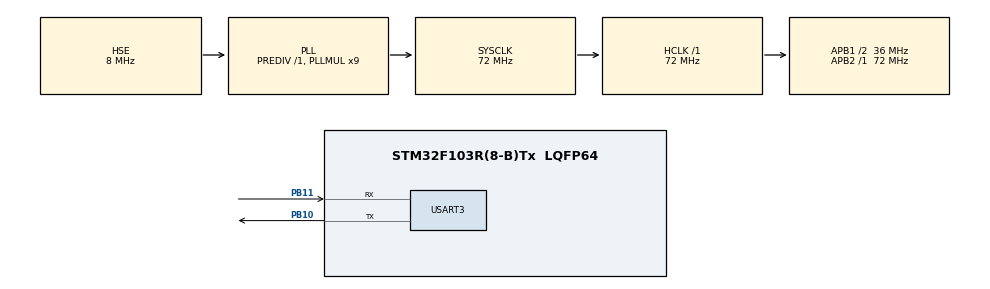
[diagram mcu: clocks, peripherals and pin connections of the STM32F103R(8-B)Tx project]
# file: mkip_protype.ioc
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IWDG.Prescaler=IWDG_PRESCALER_64
IWDG.Reload=2500
Mcu.Family=STM32F1
Mcu.Name=STM32F103R(8-B)Tx
Mcu.Package=LQFP64
NVIC.PriorityGroup=NVIC_PRIORITYGROUP_4
PA13.Mode=Serial_Wire
PA13.Signal=SYS_JTMS-SWDIO
PA14.Mode=Serial_Wire
PA14.Signal=SYS_JTCK-SWCLK
PB10.Mode=Asynchronous
PB10.Signal=USART3_TX
PB11.Mode=Asynchronous
PB11.Signal=USART3_RX
PD0-OSC_IN.Mode=HSE-External-Oscillator
PD0-OSC_IN.Signal=RCC_OSC_IN
PD1-OSC_OUT.Mode=HSE-External-Oscillator
PD1-OSC_OUT.Signal=RCC_OSC_OUT
ProjectManager.HeapSize=0x200
ProjectManager.StackSize=0x400
ProjectManager.TargetToolchain=MDK-ARM V5.32
RCC.AHBFreq_Value=72000000
RCC.APB1CLKDivider=RCC_HCLK_DIV2
RCC.APB1Freq_Value=36000000
RCC.APB1TimFreq_Value=72000000
RCC.APB2Freq_Value=72000000
RCC.APB2TimFreq_Value=72000000
RCC.HCLKFreq_Value=72000000
RCC.PLLMUL=RCC_PLL_MUL9
RCC.PLLSourceVirtual=RCC_PLLSOURCE_HSE
RCC.SYSCLKFreq_VALUE=72000000
RCC.SYSCLKSource=RCC_SYSCLKSOURCE_PLLCLK
RCC.USBFreq_Value=72000000
USART3.VirtualMode=VM_ASYNC
VP_IWDG_VS_IWDG.Mode=IWDG_Activate
board=custom

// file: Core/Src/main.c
/* USER CODE BEGIN Header */
/**
  ******************************************************************************
  * @file           : main.c
  * @brief          : Main program body
  ******************************************************************************
  * @attention
  *
  * Copyright (c) 2023 STMicroelectronics.
  * All rights reserved.
  *
  * This software is licensed under terms that can be found in the LICENSE file
  * in the root directory of this software component.
  * If no LICENSE file comes with this software, it is provided AS-IS.
  *
  ******************************************************************************
  */
/* USER CODE END Header */
#include "main.h"
#include "iwdg.h"
#include "usart.h"
#include "gpio.h"

/* USER CODE BEGIN Includes */
#include <stdio.h>
#include "megatec.h"
#include "can.h"
#include "pins.h"
#include "HW_Profile.h"
/* USER CODE END Includes */

/* USER CODE BEGIN PV */
TMyFlags g_MyFlags;  //инициализация битового поля со статусами
/* USER CODE END PV */

void SystemClock_Config(void);

int main(void)
{

  /* MCU Configuration--------------------------------------------------------*/

  /* Reset of all peripherals, Initializes the Flash interface and the Systick. */
  HAL_Init();

  /* Configure the system clock */
  SystemClock_Config();

  /* USER CODE BEGIN SysInit */
	Pins_Address_Init();
	Pins_LEDs_Init();
	RS232_Init();
  /* USER CODE END SysInit */

  /* Initialize all configured peripherals */
  MX_GPIO_Init();
  MX_USART3_UART_Init();

  /* USER CODE BEGIN 2 */
	g_MyFlags.UPS_state = UPS_NO_LINK;
	g_MyFlags.CAN_Fail = CAN_ERROR;
	HAL_Delay(100);
	#ifdef __USE_IWDG
		MX_IWDG_Init(); //инициализация сторожевого таймера
	#endif
	init_CAN();
	__enable_irq ();

	#ifdef __USE_DBG
		sprintf (buffer_TX_UART3, (char *)"MKIP_start\r\n");
		UART3_PutString (buffer_TX_UART3);
	#endif

  /* USER CODE END 2 */

  /* Infinite loop */
  while (1)
  {

    /* USER CODE BEGIN 3 */
		TaskCommUPS(); //соединение с UPSом
		TaskCAN(); //опрос CAN-контроллера
		Task_Control_LEDs (); //управление светодиодами

		#ifdef __USE_IWDG
		 IWDG_RESET(); //перезагрузка сторожевого таймера
		#endif
  }
  /* USER CODE END 3 */
}

void SystemClock_Config(void)
{
  RCC_OscInitTypeDef RCC_OscInitStruct = {0};
  RCC_ClkInitTypeDef RCC_ClkInitStruct = {0};

  /** Initializes the RCC Oscillators according to the specified parameters
  * in the RCC_OscInitTypeDef structure.
  */
  RCC_OscInitStruct.OscillatorType = RCC_OSCILLATORTYPE_LSI|RCC_OSCILLATORTYPE_HSE;
  RCC_OscInitStruct.HSEState = RCC_HSE_ON;
  RCC_OscInitStruct.HSEPredivValue = RCC_HSE_PREDIV_DIV1;
  RCC_OscInitStruct.HSIState = RCC_HSI_ON;
  RCC_OscInitStruct.LSIState = RCC_LSI_ON;
  RCC_OscInitStruct.PLL.PLLState = RCC_PLL_ON;
  RCC_OscInitStruct.PLL.PLLSource = RCC_PLLSOURCE_HSE;
  RCC_OscInitStruct.PLL.PLLMUL = RCC_PLL_MUL9;
  if (HAL_RCC_OscConfig(&RCC_OscInitStruct) != HAL_OK)
  {
    Error_Handler();
  }

  /** Initializes the CPU, AHB and APB buses clocks
  */
  RCC_ClkInitStruct.ClockType = RCC_CLOCKTYPE_HCLK|RCC_CLOCKTYPE_SYSCLK
                              |RCC_CLOCKTYPE_PCLK1|RCC_CLOCKTYPE_PCLK2;
  RCC_ClkInitStruct.SYSCLKSource = RCC_SYSCLKSOURCE_PLLCLK;
  RCC_ClkInitStruct.AHBCLKDivider = RCC_SYSCLK_DIV1;
  RCC_ClkInitStruct.APB1CLKDivider = RCC_HCLK_DIV2;
  RCC_ClkInitStruct.APB2CLKDivider = RCC_HCLK_DIV1;

  if (HAL_RCC_ClockConfig(&RCC_ClkInitStruct, FLASH_LATENCY_2) != HAL_OK)
  {
    Error_Handler();
  }
}

void Error_Handler(void)
{
  __disable_irq();
  while (1)
  {
  }
}
